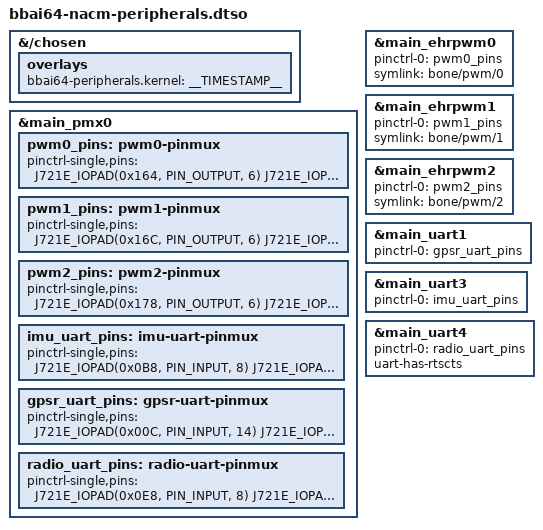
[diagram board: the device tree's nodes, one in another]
/dts-v1/;
/plugin/;

#include "ti/k3-pinctrl.h"
#include <dt-bindings/gpio/gpio.h>

&{/chosen} {
    overlays {
        bbai64-peripherals.kernel = __TIMESTAMP__;
    };
};

&main_pmx0 {
    pwm0_pins: pwm0-pinmux {
        pinctrl-single,pins = <
            J721E_IOPAD(0x164, PIN_OUTPUT, 6) /* P8_19 -> EHRPWM0A */
            J721E_IOPAD(0x168, PIN_OUTPUT, 6) /* P8_13 -> EHRPWM0B */
        >;
    };
    pwm1_pins: pwm1-pinmux {
        pinctrl-single,pins = <
            J721E_IOPAD(0x16C, PIN_OUTPUT, 6) /* P9_21 -> EHRPWM1A */
            J721E_IOPAD(0x170, PIN_OUTPUT, 6) /* P9_22 -> EHRPWM1B */
        >;
    };
    pwm2_pins: pwm2-pinmux {
        pinctrl-single,pins = <
            J721E_IOPAD(0x178, PIN_OUTPUT, 6) /* P9_14 -> EHRPWM2A */
            J721E_IOPAD(0x17c, PIN_OUTPUT, 6) /* P9_16 -> EHRPWM2B */
        >;
    };

    imu_uart_pins: imu-uart-pinmux {
        pinctrl-single,pins = <
            J721E_IOPAD(0x0B8, PIN_INPUT, 8) /* P9_12 ->  UART-3 RXD */
            J721E_IOPAD(0x0BC, PIN_OUTPUT, 8) /* P9_27 ->  UART-3 TXD */
        >;
    };

    gpsr_uart_pins: gpsr-uart-pinmux {
        pinctrl-single,pins = <
            J721E_IOPAD(0x00C, PIN_INPUT, 14)  /* P8_17 -> UART-1 RXD */
            J721E_IOPAD(0x010, PIN_OUTPUT, 14) /* P8_18 -> UART-1 TXD */
        >;
    };

    radio_uart_pins: radio-uart-pinmux {
        pinctrl-single,pins = <
            J721E_IOPAD(0x0E8, PIN_INPUT, 8)  /* P9_37 -> UART-4 RX  */
            J721E_IOPAD(0x0EC, PIN_OUTPUT, 8) /* P9_38 -> UART-4 TX  */
            J721E_IOPAD(0x084, PIN_INPUT, 8)  /* P8_31 -> UART-4 CTS */
            J721E_IOPAD(0x104, PIN_OUTPUT, 8) /* P8_32 -> UART-4 RTS */
        >;
    };
};

&main_ehrpwm0 {
    pinctrl-names = "default";
    pinctrl-0 = <&pwm0_pins>;
    status = "okay";
	symlink = "bone/pwm/0";
};

&main_ehrpwm1 {
    pinctrl-names = "default";
    pinctrl-0 = <&pwm1_pins>;
    status = "okay";
	symlink = "bone/pwm/1";
};

&main_ehrpwm2 {
    pinctrl-names = "default";
    pinctrl-0 = <&pwm2_pins>;
    status = "okay";
	symlink = "bone/pwm/2";
};

&main_uart1 {
    pinctrl-names = "default";
    pinctrl-0 = <&gpsr_uart_pins>;
    status = "okay";
};

&main_uart3 {
    pinctrl-names = "default";
    pinctrl-0 = <&imu_uart_pins>;
    status = "okay";
};

&main_uart4 {
    pinctrl-names = "default";
    pinctrl-0 = <&radio_uart_pins>;
    uart-has-rtscts;
    status = "okay";
};
